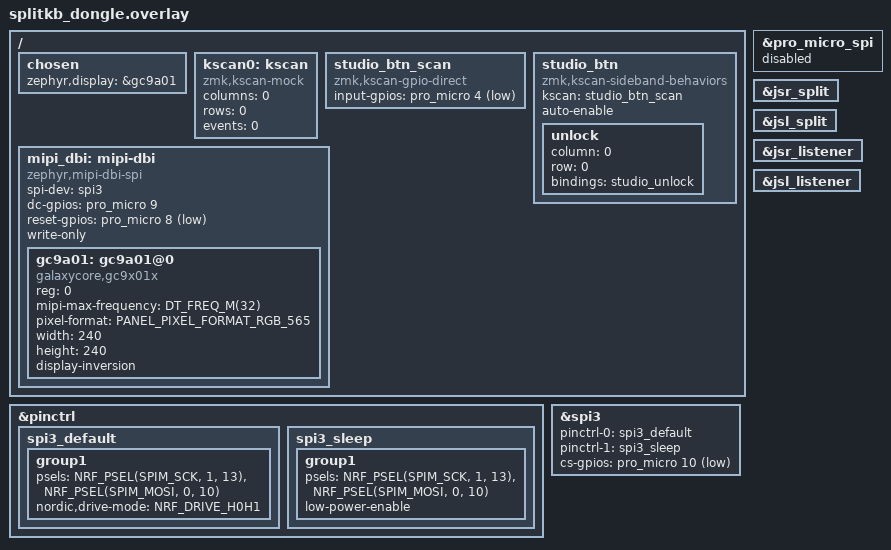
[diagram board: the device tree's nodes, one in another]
#include <zephyr/dt-bindings/display/panel.h>        // PANEL_PIXEL_FORMAT_RGB_565
#include "splitkb-common.dtsi"   // transform, splits, listeners, physical-layout

/*
 * DONGLE — o central da arquitetura com dongle. Nao tem teclas, nem joystick,
 * nem OLED: so recebe as duas metades por BLE, roda o keymap e fala com o PC
 * por USB. Tela redonda GC9A01 (240x240) via SPI/MIPI-DBI.
 *
 * >>> PINAGEM DA TELA — CONFIRA/AJUSTE QUANDO FOR FIAR <<<
 * O dongle tem quase todos os pinos livres. Usei o SPI do pro_micro
 * (&pro_micro_spi: SCK/MOSI/MISO nos pinos padrao) + 3 GPIOs de controle:
 *   SCK  -> pro_micro SCLK  (SPI, pinctrl)     MOSI -> pro_micro MOSI (SPI)
 *   CS   -> pro_micro 10                        DC   -> pro_micro 9
 *   RST  -> pro_micro 8                         BLK  -> ligar em VCC (ou GPIO)
 * GC9A01 nao usa MISO (write-only). BLK (backlight) pode ir direto no 3V3;
 * se quiser controlar por firmware, ligue num GPIO e me avise.
 *
 * >>> BOTAO DE RESET (recomendado) <<<
 * O dongle NAO consegue entrar em bootloader pelo keymap (a tecla poe em
 * bootloader a METADE onde foi apertada, nunca o dongle). Ligue um botao
 * tatil entre RST e GND: duplo-toque = bootloader pra regravar.
 */

/ {
    chosen {
        zephyr,display = &gc9a01;
    };

    /* Sem teclas: kscan mock (o keymap/Studio exige um kscan escolhido). */
    kscan0: kscan {
        compatible = "zmk,kscan-mock";
        columns = <0>;
        rows = <0>;
        events = <0>;
    };

    /*
     * BOTAO DO STUDIO (fisico, no dongle).
     *
     * O dongle nao tem teclas nem posicoes no keymap, entao o botao NAO pode
     * passar pelo keymap. Usamos "kscan sideband behaviors": ele embrulha um
     * kscan proprio e dispara a behavior DIRETO, fora do processamento do
     * keymap -- que e exatamente o caso de uso previsto pra isso.
     *
     * >>> FIACAO: botao entre o pino D4 e o GND. <<<
     * (ativo-baixo com pull-up interno, entao nao precisa de resistor externo)
     */
    studio_btn_scan: studio_btn_scan {
        compatible = "zmk,kscan-gpio-direct";
        input-gpios = <&pro_micro 4 (GPIO_ACTIVE_LOW | GPIO_PULL_UP)>;
    };

    studio_btn: studio_btn {
        compatible = "zmk,kscan-sideband-behaviors";
        kscan = <&studio_btn_scan>;
        auto-enable;

        /* uma tecla so -> linha e coluna 0 */
        unlock {
            column = <0>;
            row = <0>;
            bindings = <&studio_unlock>;
        };
    };
};

/*
 * BARRAMENTO DA TELA: SPIM3, nao o pro_micro_spi.
 * O pro_micro_spi do nice!nano e o SPIM1, que tem TETO FISICO de 8MHz no
 * nRF52840 -- pedir mais seria aceito em silencio e clampado. So o SPIM3
 * chega a 32MHz (e por isso que o prospector roda a 30MHz+). Mesmos pinos
 * fisicos (SCK=P1.13/D15, MOSI=P0.10/D16), so troca o periferico interno.
 * SPIM3 so faz 8/16/32MHz -- nao existe degrau de 24.
 * MISO omitido de proposito: GC9A01 e write-only, e isso libera o D14.
 */
&pro_micro_spi { status = "disabled"; };

&pinctrl {
    spi3_default: spi3_default {
        group1 {
            psels = <NRF_PSEL(SPIM_SCK, 1, 13)>,
                    <NRF_PSEL(SPIM_MOSI, 0, 10)>;
            nordic,drive-mode = <NRF_DRIVE_H0H1>;   /* drive alto: exigido a 32MHz */
        };
    };
    spi3_sleep: spi3_sleep {
        group1 {
            psels = <NRF_PSEL(SPIM_SCK, 1, 13)>,
                    <NRF_PSEL(SPIM_MOSI, 0, 10)>;
            low-power-enable;
        };
    };
};

&spi3 {
    status = "okay";
    pinctrl-0 = <&spi3_default>;
    pinctrl-1 = <&spi3_sleep>;
    pinctrl-names = "default", "sleep";
    cs-gpios = <&pro_micro 10 GPIO_ACTIVE_LOW>;    /* CS da tela */
};

/ {
    /* Controlador MIPI-DBI (modo SPI 4 fios): usa o barramento acima + DC/RST.
     * Fica top-level e aponta pro barramento via spi-dev (padrao do binding). */
    mipi_dbi: mipi-dbi {
        compatible = "zephyr,mipi-dbi-spi";
        #address-cells = <1>;
        #size-cells = <0>;
        spi-dev = <&spi3>;
        dc-gpios = <&pro_micro 9 GPIO_ACTIVE_HIGH>;
        reset-gpios = <&pro_micro 8 GPIO_ACTIVE_LOW>;
        write-only;                 /* GC9A01 nao le -> dispensa MISO */

        gc9a01: gc9a01@0 {
            compatible = "galaxycore,gc9x01x";
            reg = <0>;
            /* Tela SOLDADA (2026-07-19). 16MHz validado no teste; 32MHz e o
             * maximo do SPIM3 (frame cheio ~29ms). Se algum dia aparecer
             * artefato, degrau seguro de volta e DT_FREQ_M(16). */
            mipi-max-frequency = <DT_FREQ_M(32)>;
            /* modo SPI 4 fios (Type C3) e o default do mipi-dbi-spi */
            pixel-format = <PANEL_PIXEL_FORMAT_RGB_565>;
            width = <240>;
            height = <240>;
            display-inversion;      /* GC9A01 tipico: cores invertidas sem isso */
        };
    };
};

/*
 * Central: escuta os DOIS joysticks (cada um chega pela split no seu reg).
 * Sem device aqui (modo proxy/central); o device fica em cada periferico.
 */
&jsr_split { status = "okay"; };    /* joystick direito (reg=0) */
&jsl_split { status = "okay"; };    /* joystick esquerdo (reg=1) */

&jsr_listener { status = "okay"; };  /* direito: cursor, scroll na layer 1 */
&jsl_listener { status = "okay"; };  /* esquerdo: cursor */
